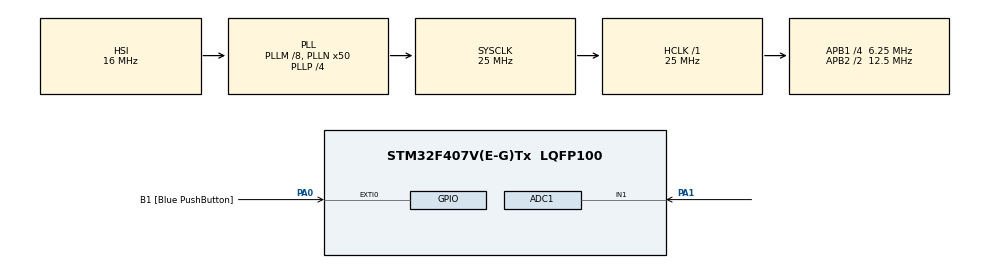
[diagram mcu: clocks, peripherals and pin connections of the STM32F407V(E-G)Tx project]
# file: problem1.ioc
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ADC1.Channel-0\#ChannelRegularConversion=ADC_CHANNEL_1
ADC1.ContinuousConvMode=ENABLE
ADC1.NbrOfConversionFlag=1
ADC1.Rank-0\#ChannelRegularConversion=1
ADC1.SamplingTime-0\#ChannelRegularConversion=ADC_SAMPLETIME_3CYCLES
ADC1.master=1
Dma.ADC1.0.Direction=DMA_PERIPH_TO_MEMORY
Dma.ADC1.0.FIFOMode=DMA_FIFOMODE_DISABLE
Dma.ADC1.0.Instance=DMA2_Stream0
Dma.ADC1.0.MemDataAlignment=DMA_MDATAALIGN_WORD
Dma.ADC1.0.MemInc=DMA_MINC_ENABLE
Dma.ADC1.0.Mode=DMA_CIRCULAR
Dma.ADC1.0.PeriphDataAlignment=DMA_PDATAALIGN_WORD
Dma.ADC1.0.PeriphInc=DMA_PINC_DISABLE
Dma.ADC1.0.Priority=DMA_PRIORITY_LOW
Dma.Request0=ADC1
Mcu.Family=STM32F4
Mcu.Name=STM32F407V(E-G)Tx
Mcu.Package=LQFP100
NVIC.ADC_IRQn=true\:0\:0\:false\:false\:true\:true\:true\:true
NVIC.DMA2_Stream0_IRQn=true\:0\:0\:false\:false\:true\:false\:true\:true
NVIC.EXTI0_IRQn=true\:0\:5\:false\:false\:true\:true\:true\:true
NVIC.PriorityGroup=NVIC_PRIORITYGROUP_0
PA0-WKUP.GPIO_Label=B1 [Blue PushButton]
PA0-WKUP.Signal=GPXTI0
PA1.Signal=ADCx_IN1
PA10.GPIO_Label=OTG_FS_ID
PA10.GPIO_Mode=GPIO_MODE_AF_PP
PA10.GPIO_PuPd=GPIO_NOPULL
PA10.GPIO_Speed=GPIO_SPEED_FREQ_LOW
PA10.Signal=USB_OTG_FS_ID
PA11.GPIO_Label=OTG_FS_DM
PA11.GPIO_Mode=GPIO_MODE_AF_PP
PA11.GPIO_PuPd=GPIO_NOPULL
PA11.GPIO_Speed=GPIO_SPEED_FREQ_LOW
PA11.Signal=USB_OTG_FS_DM
PA12.GPIO_Label=OTG_FS_DP
PA12.GPIO_Mode=GPIO_MODE_AF_PP
PA12.GPIO_PuPd=GPIO_NOPULL
PA12.GPIO_Speed=GPIO_SPEED_FREQ_LOW
PA12.Signal=USB_OTG_FS_DP
PA13.GPIO_Label=SWDIO
PA13.Signal=SYS_JTMS-SWDIO
PA14.GPIO_Label=SWCLK
PA14.Signal=SYS_JTCK-SWCLK
PA9.GPIO_Label=VBUS_FS
PA9.GPIO_Mode=GPIO_MODE_INPUT
PA9.GPIO_PuPd=GPIO_NOPULL
PA9.Signal=USB_OTG_FS_VBUS
PB3.GPIO_Label=SWO
PB3.Signal=SYS_JTDO-SWO
PB6.GPIO_Label=Audio_SCL [CS43L22_SCL]
PB6.GPIO_Mode=GPIO_MODE_AF_OD
PB6.GPIO_PuPd=GPIO_NOPULL
PB6.GPIO_Speed=GPIO_SPEED_FREQ_LOW
PB6.Signal=I2C1_SCL
PB9.GPIO_Label=Audio_SDA [CS43L22_SDA]
PB9.GPIO_Mode=GPIO_MODE_AF_OD
PB9.GPIO_PuPd=GPIO_NOPULL
PB9.GPIO_Speed=GPIO_SPEED_FREQ_LOW
PB9.Signal=I2C1_SDA
PC10.GPIO_Label=I2S3_SCK [CS43L22_SCLK]
PC10.GPIO_Mode=GPIO_MODE_AF_PP
PC10.GPIO_PuPd=GPIO_NOPULL
PC10.GPIO_Speed=GPIO_SPEED_FREQ_LOW
PC10.Signal=I2S3_CK
PC12.GPIO_Label=I2S3_SD [CS43L22_SDIN]
PC12.GPIO_Mode=GPIO_MODE_AF_PP
PC12.GPIO_PuPd=GPIO_NOPULL
PC12.GPIO_Speed=GPIO_SPEED_FREQ_LOW
PC12.Signal=I2S3_SD
PC14-OSC32_IN.GPIO_Label=PC14-OSC32_IN
PC14-OSC32_IN.Signal=RCC_OSC32_IN
PC15-OSC32_OUT.GPIO_Label=PC15-OSC32_OUT
PC15-OSC32_OUT.Signal=RCC_OSC32_OUT
PC3.GPIO_Label=PDM_OUT [MP45DT02_DOUT]
PC3.GPIO_Mode=GPIO_MODE_AF_PP
PC3.GPIO_PuPd=GPIO_NOPULL
PC3.GPIO_Speed=GPIO_SPEED_FREQ_LOW
PC3.Signal=I2S2_SD
PC7.GPIO_Label=I2S3_MCK [CS43L22_MCLK]
PC7.GPIO_Mode=GPIO_MODE_AF_PP
PC7.GPIO_PuPd=GPIO_NOPULL
PC7.GPIO_Speed=GPIO_SPEED_FREQ_LOW
PC7.Signal=I2S3_MCK
PH0-OSC_IN.GPIO_Label=PH0-OSC_IN
PH0-OSC_IN.Signal=RCC_OSC_IN
PH1-OSC_OUT.GPIO_Label=PH1-OSC_OUT
PH1-OSC_OUT.Signal=RCC_OSC_OUT
ProjectManager.HeapSize=0x200
ProjectManager.StackSize=0x400
ProjectManager.TargetToolchain=STM32CubeIDE
RCC.48MHZClocksFreq_Value=14285714.285714285
RCC.AHBFreq_Value=25000000
RCC.APB1CLKDivider=RCC_HCLK_DIV4
RCC.APB1Freq_Value=6250000
RCC.APB1TimFreq_Value=12500000
RCC.APB2CLKDivider=RCC_HCLK_DIV2
RCC.APB2Freq_Value=12500000
RCC.APB2TimFreq_Value=25000000
RCC.CortexFreq_Value=25000000
RCC.HCLKFreq_Value=25000000
RCC.HSE_VALUE=8000000
RCC.HSI_VALUE=16000000
RCC.LSE_VALUE=32768
RCC.PLLM=8
RCC.PLLN=50
RCC.PLLP=RCC_PLLP_DIV4
RCC.PLLQ=7
RCC.SYSCLKFreq_VALUE=25000000
RCC.SYSCLKSource=RCC_SYSCLKSOURCE_PLLCLK
RCC.VCOOutputFreq_Value=100000000
SH.ADCx_IN1.0=ADC1_IN1,IN1
board=STM32F407G-DISC1

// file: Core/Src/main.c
/* USER CODE BEGIN Header */
/**
  ******************************************************************************
  * @file           : main.c
  * @brief          : Main program body
  ******************************************************************************
  * @attention
  *
  * Copyright (c) 2024 STMicroelectronics.
  * All rights reserved.
  *
  * This software is licensed under terms that can be found in the LICENSE file
  * in the root directory of this software component.
  * If no LICENSE file comes with this software, it is provided AS-IS.
  *
  ******************************************************************************
  */
/* USER CODE END Header */
#include "main.h"

/* USER CODE BEGIN PTD */
#define RCC_GPIOD_ER (0x40023830UL)
#define GPIOD_MODER (0x40020c00UL)
#define GPIOD_ODR (0x40020c14UL)
#define adc1smp1 (0x4001200cUL)
/* USER CODE END PTD */

ADC_HandleTypeDef hadc1;
DMA_HandleTypeDef hdma_adc1;

/* USER CODE BEGIN PV */
uint32_t buffer;
uint32_t *rccgpiod = (uint32_t *) RCC_GPIOD_ER;
uint32_t *gpiodmoder= (uint32_t *) GPIOD_MODER;
uint32_t *gpiododr = (uint32_t *) GPIOD_ODR;
uint32_t * adcsmp1 = (uint32_t *) adc1smp1;
uint8_t goSleep = 0;

/* USER CODE END PV */

void SystemClock_Config(void);
static void MX_GPIO_Init(void);
static void MX_DMA_Init(void);
static void MX_ADC1_Init(void);

/* USER CODE BEGIN 0 */
uint32_t map(uint16_t value){
	return value*16;
}

void HAL_ADC_ConvCpltCallback(ADC_HandleTypeDef* hadc)
{
	HAL_ADC_Start_DMA(&hadc1, &buffer, 1);
}

void HAL_GPIO_EXTI_Callback(uint16_t GPIO_Pin)
{
	goSleep=0;
	if(map(buffer)>=49140){
		//HAL_GPIO_TogglePin(GPIOD, GPIO_PIN_15);
		*rccgpiod |= (1<<3);
		*gpiodmoder|=(1<<30);
		*gpiododr |= (1<<15);
	}
	else if(map(buffer)>=32760){
		//HAL_GPIO_TogglePin(GPIOD, GPIO_PIN_14);
		*rccgpiod |= (1<<3);
		*gpiodmoder|=(1<<28);
		*gpiododr |= (1<<14);
	}
	else if (map(buffer)>=16380){
		//HAL_GPIO_TogglePin(GPIOD, GPIO_PIN_13);
		*rccgpiod |= (1<<3);
		*gpiodmoder|=(1<<26);
		*gpiododr |= (1<<13);
	}
	else {
		//HAL_GPIO_TogglePin(GPIOD, GPIO_PIN_12);
		*rccgpiod |= (1<<3);
		*gpiodmoder|=(1<<24);
		*gpiododr |= (1<<12);
	}
	goSleep=1;
}

/* USER CODE END 0 */

int main(void)
{

  /* MCU Configuration--------------------------------------------------------*/

  /* Reset of all peripherals, Initializes the Flash interface and the Systick. */
  HAL_Init();

  /* Configure the system clock */
  SystemClock_Config();

  /* Initialize all configured peripherals */
  MX_GPIO_Init();
  MX_DMA_Init();
  MX_ADC1_Init();
  /* USER CODE BEGIN 2 */

  	 *adcsmp1 &=~(0b111 <<3);
	HAL_ADC_Start_DMA(&hadc1, &buffer, 1);

	HAL_SuspendTick();
	HAL_PWR_EnterSTOPMode(PWR_MAINREGULATOR_ON, PWR_STOPENTRY_WFI);
	HAL_ResumeTick();

  /* USER CODE END 2 */

  /* Infinite loop */
  while (1)
  {

  }
}

void SystemClock_Config(void)
{
  RCC_OscInitTypeDef RCC_OscInitStruct = {0};
  RCC_ClkInitTypeDef RCC_ClkInitStruct = {0};

  /** Configure the main internal regulator output voltage
  */
  __HAL_RCC_PWR_CLK_ENABLE();
  __HAL_PWR_VOLTAGESCALING_CONFIG(PWR_REGULATOR_VOLTAGE_SCALE1);

  /** Initializes the RCC Oscillators according to the specified parameters
  * in the RCC_OscInitTypeDef structure.
  */
  RCC_OscInitStruct.OscillatorType = RCC_OSCILLATORTYPE_HSI;
  RCC_OscInitStruct.HSIState = RCC_HSI_ON;
  RCC_OscInitStruct.HSICalibrationValue = RCC_HSICALIBRATION_DEFAULT;
  RCC_OscInitStruct.PLL.PLLState = RCC_PLL_ON;
  RCC_OscInitStruct.PLL.PLLSource = RCC_PLLSOURCE_HSI;
  RCC_OscInitStruct.PLL.PLLM = 8;
  RCC_OscInitStruct.PLL.PLLN = 50;
  RCC_OscInitStruct.PLL.PLLP = RCC_PLLP_DIV4;
  RCC_OscInitStruct.PLL.PLLQ = 7;
  if (HAL_RCC_OscConfig(&RCC_OscInitStruct) != HAL_OK)
  {
    Error_Handler();
  }

  /** Initializes the CPU, AHB and APB buses clocks
  */
  RCC_ClkInitStruct.ClockType = RCC_CLOCKTYPE_HCLK|RCC_CLOCKTYPE_SYSCLK
                              |RCC_CLOCKTYPE_PCLK1|RCC_CLOCKTYPE_PCLK2;
  RCC_ClkInitStruct.SYSCLKSource = RCC_SYSCLKSOURCE_PLLCLK;
  RCC_ClkInitStruct.AHBCLKDivider = RCC_SYSCLK_DIV1;
  RCC_ClkInitStruct.APB1CLKDivider = RCC_HCLK_DIV4;
  RCC_ClkInitStruct.APB2CLKDivider = RCC_HCLK_DIV2;

  if (HAL_RCC_ClockConfig(&RCC_ClkInitStruct, FLASH_LATENCY_0) != HAL_OK)
  {
    Error_Handler();
  }
}

static void MX_ADC1_Init(void)
{

  ADC_ChannelConfTypeDef sConfig = {0};

  /** Configure the global features of the ADC (Clock, Resolution, Data Alignment and number of conversion)
  */
  hadc1.Instance = ADC1;
  hadc1.Init.ClockPrescaler = ADC_CLOCK_SYNC_PCLK_DIV2;
  hadc1.Init.Resolution = ADC_RESOLUTION_12B;
  hadc1.Init.ScanConvMode = DISABLE;
  hadc1.Init.ContinuousConvMode = ENABLE;
  hadc1.Init.DiscontinuousConvMode = DISABLE;
  hadc1.Init.ExternalTrigConvEdge = ADC_EXTERNALTRIGCONVEDGE_NONE;
  hadc1.Init.ExternalTrigConv = ADC_SOFTWARE_START;
  hadc1.Init.DataAlign = ADC_DATAALIGN_RIGHT;
  hadc1.Init.NbrOfConversion = 1;
  hadc1.Init.DMAContinuousRequests = DISABLE;
  hadc1.Init.EOCSelection = ADC_EOC_SINGLE_CONV;
  if (HAL_ADC_Init(&hadc1) != HAL_OK)
  {
    Error_Handler();
  }

  /** Configure for the selected ADC regular channel its corresponding rank in the sequencer and its sample time.
  */
  sConfig.Channel = ADC_CHANNEL_1;
  sConfig.Rank = 1;
  sConfig.SamplingTime = ADC_SAMPLETIME_3CYCLES;
  if (HAL_ADC_ConfigChannel(&hadc1, &sConfig) != HAL_OK)
  {
    Error_Handler();
  }

}

static void MX_DMA_Init(void)
{

  /* DMA controller clock enable */
  __HAL_RCC_DMA2_CLK_ENABLE();

  /* DMA interrupt init */
  /* DMA2_Stream0_IRQn interrupt configuration */
  HAL_NVIC_SetPriority(DMA2_Stream0_IRQn, 0, 0);
  HAL_NVIC_EnableIRQ(DMA2_Stream0_IRQn);

}

static void MX_GPIO_Init(void)
{
  GPIO_InitTypeDef GPIO_InitStruct = {0};

  /* GPIO Ports Clock Enable */
  __HAL_RCC_GPIOC_CLK_ENABLE();
  __HAL_RCC_GPIOH_CLK_ENABLE();
  __HAL_RCC_GPIOA_CLK_ENABLE();
  __HAL_RCC_GPIOB_CLK_ENABLE();

  /*Configure GPIO pin : B1_Pin */
  GPIO_InitStruct.Pin = B1_Pin;
  GPIO_InitStruct.Mode = GPIO_MODE_IT_RISING;
  GPIO_InitStruct.Pull = GPIO_NOPULL;
  HAL_GPIO_Init(B1_GPIO_Port, &GPIO_InitStruct);

  /* EXTI interrupt init*/
  HAL_NVIC_SetPriority(EXTI0_IRQn, 0, 5);
  HAL_NVIC_EnableIRQ(EXTI0_IRQn);

}

void Error_Handler(void)
{
  __disable_irq();
  while (1)
  {
  }
}
